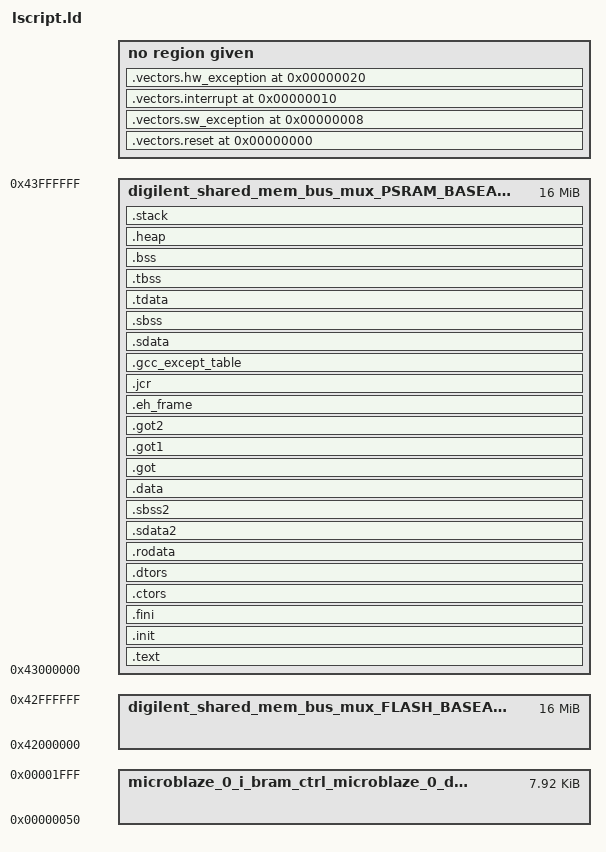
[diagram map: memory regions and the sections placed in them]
/*******************************************************************/
/*                                                                 */
/* This file is automatically generated by linker script generator.*/
/*                                                                 */
/* Version: Xilinx EDK 14.2 EDK_P.28xd                                */
/*                                                                 */
/* Copyright (c) 2010 Xilinx, Inc.  All rights reserved.           */
/*                                                                 */
/* Description : MicroBlaze Linker Script                          */
/*                                                                 */
/*******************************************************************/

_STACK_SIZE = DEFINED(_STACK_SIZE) ? _STACK_SIZE : 0x418;
_HEAP_SIZE = DEFINED(_HEAP_SIZE) ? _HEAP_SIZE : 0x418;

/* Define Memories in the system */

MEMORY
{
   microblaze_0_i_bram_ctrl_microblaze_0_d_bram_ctrl : ORIGIN = 0x00000050, LENGTH = 0x00001FB0
   digilent_shared_mem_bus_mux_PSRAM_BASEADDR : ORIGIN = 0x43000000, LENGTH = 0x01000000
   digilent_shared_mem_bus_mux_FLASH_BASEADDR : ORIGIN = 0x42000000, LENGTH = 0x01000000
}

/* Specify the default entry point to the program */

ENTRY(_start)

/* Define the sections, and where they are mapped in memory */

SECTIONS
{
.vectors.reset 0x00000000 : {
   *(.vectors.reset)
} 

.vectors.sw_exception 0x00000008 : {
   *(.vectors.sw_exception)
} 

.vectors.interrupt 0x00000010 : {
   *(.vectors.interrupt)
} 

.vectors.hw_exception 0x00000020 : {
   *(.vectors.hw_exception)
} 

.text : {
   *(.text)
   *(.text.*)
   *(.gnu.linkonce.t.*)
} > digilent_shared_mem_bus_mux_PSRAM_BASEADDR

.init : {
   KEEP (*(.init))
} > digilent_shared_mem_bus_mux_PSRAM_BASEADDR

.fini : {
   KEEP (*(.fini))
} > digilent_shared_mem_bus_mux_PSRAM_BASEADDR

.ctors : {
   __CTOR_LIST__ = .;
   ___CTORS_LIST___ = .;
   KEEP (*crtbegin.o(.ctors))
   KEEP (*(EXCLUDE_FILE(*crtend.o) .ctors))
   KEEP (*(SORT(.ctors.*)))
   KEEP (*(.ctors))
   __CTOR_END__ = .;
   ___CTORS_END___ = .;
} > digilent_shared_mem_bus_mux_PSRAM_BASEADDR

.dtors : {
   __DTOR_LIST__ = .;
   ___DTORS_LIST___ = .;
   KEEP (*crtbegin.o(.dtors))
   KEEP (*(EXCLUDE_FILE(*crtend.o) .dtors))
   KEEP (*(SORT(.dtors.*)))
   KEEP (*(.dtors))
   PROVIDE(__DTOR_END__ = .);
   PROVIDE(___DTORS_END___ = .);
} > digilent_shared_mem_bus_mux_PSRAM_BASEADDR

.rodata : {
   __rodata_start = .;
   *(.rodata)
   *(.rodata.*)
   *(.gnu.linkonce.r.*)
   __rodata_end = .;
} > digilent_shared_mem_bus_mux_PSRAM_BASEADDR

.sdata2 : {
   . = ALIGN(8);
   __sdata2_start = .;
   *(.sdata2)
   *(.sdata2.*)
   *(.gnu.linkonce.s2.*)
   . = ALIGN(8);
   __sdata2_end = .;
} > digilent_shared_mem_bus_mux_PSRAM_BASEADDR

.sbss2 : {
   __sbss2_start = .;
   *(.sbss2)
   *(.sbss2.*)
   *(.gnu.linkonce.sb2.*)
   __sbss2_end = .;
} > digilent_shared_mem_bus_mux_PSRAM_BASEADDR

.data : {
   . = ALIGN(4);
   __data_start = .;
   *(.data)
   *(.data.*)
   *(.gnu.linkonce.d.*)
   __data_end = .;
} > digilent_shared_mem_bus_mux_PSRAM_BASEADDR

.got : {
   *(.got)
} > digilent_shared_mem_bus_mux_PSRAM_BASEADDR

.got1 : {
   *(.got1)
} > digilent_shared_mem_bus_mux_PSRAM_BASEADDR

.got2 : {
   *(.got2)
} > digilent_shared_mem_bus_mux_PSRAM_BASEADDR

.eh_frame : {
   *(.eh_frame)
} > digilent_shared_mem_bus_mux_PSRAM_BASEADDR

.jcr : {
   *(.jcr)
} > digilent_shared_mem_bus_mux_PSRAM_BASEADDR

.gcc_except_table : {
   *(.gcc_except_table)
} > digilent_shared_mem_bus_mux_PSRAM_BASEADDR

.sdata : {
   . = ALIGN(8);
   __sdata_start = .;
   *(.sdata)
   *(.sdata.*)
   *(.gnu.linkonce.s.*)
   __sdata_end = .;
} > digilent_shared_mem_bus_mux_PSRAM_BASEADDR

.sbss (NOLOAD) : {
   . = ALIGN(4);
   __sbss_start = .;
   *(.sbss)
   *(.sbss.*)
   *(.gnu.linkonce.sb.*)
   . = ALIGN(8);
   __sbss_end = .;
} > digilent_shared_mem_bus_mux_PSRAM_BASEADDR

.tdata : {
   __tdata_start = .;
   *(.tdata)
   *(.tdata.*)
   *(.gnu.linkonce.td.*)
   __tdata_end = .;
} > digilent_shared_mem_bus_mux_PSRAM_BASEADDR

.tbss : {
   __tbss_start = .;
   *(.tbss)
   *(.tbss.*)
   *(.gnu.linkonce.tb.*)
   __tbss_end = .;
} > digilent_shared_mem_bus_mux_PSRAM_BASEADDR

.bss (NOLOAD) : {
   . = ALIGN(4);
   __bss_start = .;
   *(.bss)
   *(.bss.*)
   *(.gnu.linkonce.b.*)
   *(COMMON)
   . = ALIGN(4);
   __bss_end = .;
} > digilent_shared_mem_bus_mux_PSRAM_BASEADDR

_SDA_BASE_ = __sdata_start + ((__sbss_end - __sdata_start) / 2 );

_SDA2_BASE_ = __sdata2_start + ((__sbss2_end - __sdata2_start) / 2 );

/* Generate Stack and Heap definitions */

.heap (NOLOAD) : {
   . = ALIGN(8);
   _heap = .;
   _heap_start = .;
   . += _HEAP_SIZE;
   _heap_end = .;
} > digilent_shared_mem_bus_mux_PSRAM_BASEADDR

.stack (NOLOAD) : {
   _stack_end = .;
   . += _STACK_SIZE;
   . = ALIGN(8);
   _stack = .;
   __stack = _stack;
} > digilent_shared_mem_bus_mux_PSRAM_BASEADDR

_end = .;
}

